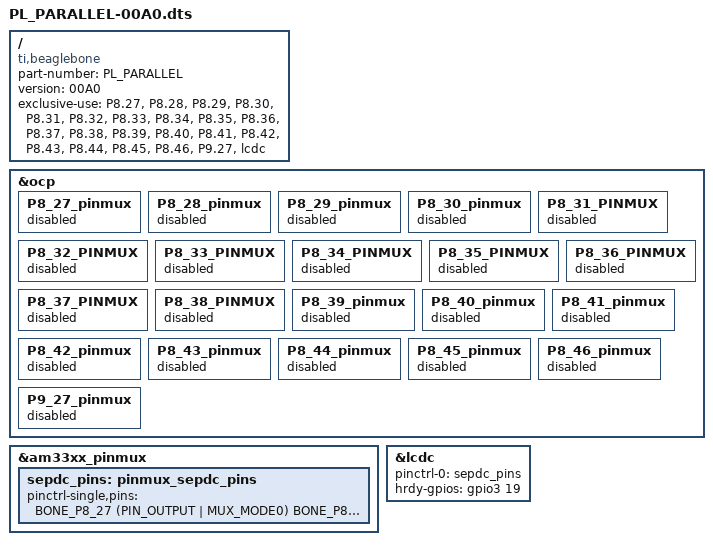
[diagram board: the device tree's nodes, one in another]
/*
 * Copyright (C) 2021 PL Germany
 *
 * Cape for PL_PARALLEL
 *
 * License stuff !!!
 */
/dts-v1/;
/plugin/;

#include "gpio.h"
#include "am33xx.h"
#include "am335x-bbw-bbb-base.h"

/{
    compatible = "ti,beaglebone", "ti,beaglebone-black";

    /* identification */
    part-number = "PL_PARALLEL";
    version = "00A0";

    /* state the resources this cape uses */
    exclusive-use = 
        /* Pin header */
        "P8.27", /* LCD_VSYNC */
        "P8.28", /* LCD_PCLK */
        "P8.29", /* LCD_HSYNC */
        "P8.30", /* LCD_AC_BIAS_EN */
        "P8.31", /* LDC_DATA_14 */
        "P8.32", /* LCD_DATA_15 */
        "P8.33", /* LCD_DATA_13 */
        "P8.34", /* LCD_DATA_11 */
        "P8.35", /* LCD_DATA_12 */
        "P8.36", /* LCD_DATA_10 */
        "P8.37", /* LCD_DATA_8 */
        "P8.38", /* LCD_DATA_9 */
        "P8.39", /* LCD_DATA_6 */
        "P8.40", /* LCD_DATA_7 */
        "P8.41", /* LCD_DATA_4 */
        "P8.42", /* LCD_DATA_5 */
        "P8.43", /* LCD_DATA_2 */
        "P8.44", /* LCD_DATA_3 */
        "P8.45", /* LCD_DATA_0 */
        "P8.46", /* LCD_DATA_1 */
        "P9.27", /* HRDY GPIO */
        /* Hardware ip */
        "lcdc"; /* HW Registers + Interrupt */

    /*
     * Free up the pins used by the driver from the pinmux helpers.
     */
    fragment@0 {
        target = <&ocp>;
        __overlay__ {
            P8_27_pinmux { status = "disabled"; }; /* LCD_VSYNC */
            P8_28_pinmux { status = "disabled"; }; /* LCD_PCLK */
            P8_29_pinmux { status = "disabled"; }; /* LCD_HSYNC */
            P8_30_pinmux { status = "disabled"; }; /* LCD_AC_BIAS_EN */
            P8_31_PINMUX { status = "disabled"; }; /* LDC_DATA_14 */
            P8_32_PINMUX { status = "disabled"; }; /* LCD_DATA_15 */
            P8_33_PINMUX { status = "disabled"; }; /* LCD_DATA_13 */
            P8_34_PINMUX { status = "disabled"; }; /* LCD_DATA_11 */
            P8_35_PINMUX { status = "disabled"; }; /* LCD_DATA_12 */
            P8_36_PINMUX { status = "disabled"; }; /* LCD_DATA_10 */
            P8_37_PINMUX { status = "disabled"; }; /* LCD_DATA_8 */
            P8_38_PINMUX { status = "disabled"; }; /* LCD_DATA_9 */
            P8_39_pinmux { status = "disabled"; }; /* LCD_DATA_6 */
            P8_40_pinmux { status = "disabled"; }; /* LCD_DATA_7 */
            P8_41_pinmux { status = "disabled"; }; /* LCD_DATA_4 */
            P8_42_pinmux { status = "disabled"; }; /* LCD_DATA_5 */
            P8_43_pinmux { status = "disabled"; }; /* LCD_DATA_2 */
            P8_44_pinmux { status = "disabled"; }; /* LCD_DATA_3 */
            P8_45_pinmux { status = "disabled"; }; /* LCD_DATA_0 */
            P8_46_pinmux { status = "disabled"; }; /* LCD_DATA_1 */
            P9_27_pinmux { status = "disabled"; }; /* HRDY GPIO */
        };
    };

    fragment@1 {
        target = <&am33xx_pinmux>;
        __overlay__ {
            sepdc_pins: pinmux_sepdc_pins {
                pinctrl-single,pins = <
                    BONE_P8_27 (PIN_OUTPUT | MUX_MODE0) /*0x0E0 ((1 << 3) | 0) /* P8.27 - LCD_VSYNC -> fast slew, PUPD disabled, Receiver disabled, Mode 0 */
                    BONE_P8_28 (PIN_OUTPUT | MUX_MODE0) /*0x0E8 ((1 << 3) | 0) /* P8.28 - LCD_PCLK -> fast slew, PUPD disabled, Receiver disabled, Mode 0 */
                    BONE_P8_29 (PIN_OUTPUT | MUX_MODE0) /*0x0E4 ((1 << 3) | 0) /* P8.29 - LCD_HSYNC -> fast slew, PUPD disabled, Receiver disabled, Mode 0 */
                    BONE_P8_30 (PIN_OUTPUT | MUX_MODE0) /*0x0EC ((1 << 3) | 0) /* P8.30 - LCD_AC_BIAS_EN -> fast slew, PUPD disabled, Receiver disabled, Mode 0 */
                    BONE_P8_31 (PIN_INPUT | MUX_MODE0) /* LDC_DATA_14 */
                    BONE_P8_32 (PIN_INPUT | MUX_MODE0) /* LCD_DATA_15 */
                    BONE_P8_33 (PIN_INPUT | MUX_MODE0) /* LCD_DATA_13 */
                    BONE_P8_34 (PIN_INPUT | MUX_MODE0) /* LCD_DATA_11 */
                    BONE_P8_35 (PIN_INPUT | MUX_MODE0) /* LCD_DATA_12 */
                    BONE_P8_36 (PIN_INPUT | MUX_MODE0) /* LCD_DATA_10 */
                    BONE_P8_37 (PIN_INPUT | MUX_MODE0) /* LCD_DATA_8 */
                    BONE_P8_38 (PIN_INPUT | MUX_MODE0) /* LCD_DATA_9 */
                    BONE_P8_39 (PIN_INPUT | MUX_MODE0) /*0x0B8 ((1 << 3) | 0) /* P8.39 - LCD_DATA_6 -> fast slew, PUPD disabled, Receiver disabled, Mode 0 */
                    BONE_P8_40 (PIN_INPUT | MUX_MODE0) /*0x0BC ((1 << 3) | 0) /* P8.40 - LCD_DATA_7 -> fast slew, PUPD disabled, Receiver disabled, Mode 0 */
                    BONE_P8_41 (PIN_INPUT | MUX_MODE0) /*0x0B0 ((1 << 3) | 0) /* P8.41 - LCD_DATA_4 -> fast slew, PUPD disabled, Receiver disabled, Mode 0 */
                    BONE_P8_42 (PIN_INPUT | MUX_MODE0) /*0x0B4 ((1 << 3) | 0) /* P8.42 - LCD_DATA_5 -> fast slew, PUPD disabled, Receiver disabled, Mode 0 */
                    BONE_P8_43 (PIN_INPUT | MUX_MODE0) /*0x0AB ((1 << 3) | 0) /* P8.43 - LCD_DATA_2 -> fast slew, PUPD disabled, Receiver disabled, Mode 0 */
                    BONE_P8_44 (PIN_INPUT | MUX_MODE0) /*0x0AC ((1 << 3) | 0) /* P8.44 - LCD_DATA_3 -> fast slew, PUPD disabled, Receiver disabled, Mode 0 */
                    BONE_P8_45 (PIN_INPUT | MUX_MODE0) /*0x0A0 ((1 << 3) | 0) /* P8.45 - LCD_DATA_0 -> fast slew, PUPD disabled, Receiver disabled, Mode 0 */
                    BONE_P8_46 (PIN_INPUT | MUX_MODE0) /*0x0A4 ((1 << 3) | 0) /* P8.46 - LCD_DATA_1 -> fast slew, PUPD disabled, Receiver disabled, Mode 0 */
                    BONE_P9_27 (PIN_INPUT | MUX_MODE7)
                >;
            };
        };
    };

    fragment@2 {
        target = <&lcdc>;
        __overlay__ {
            status = "okay";
            pinctrl-names = "default";
            pinctrl-0 = <&sepdc_pins>;

            hrdy-gpios = <&gpio3 19 0>;
        };
    };
};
